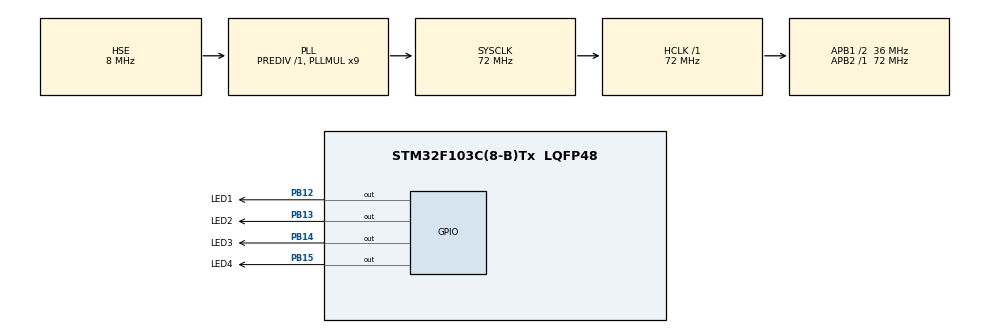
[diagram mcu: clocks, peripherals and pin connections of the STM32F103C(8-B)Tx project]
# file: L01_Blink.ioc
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Mcu.Family=STM32F1
Mcu.Name=STM32F103C(8-B)Tx
Mcu.Package=LQFP48
NVIC.PriorityGroup=NVIC_PRIORITYGROUP_4
PA13.Mode=Serial_Wire
PA13.Signal=SYS_JTMS-SWDIO
PA14.Mode=Serial_Wire
PA14.Signal=SYS_JTCK-SWCLK
PB12.GPIO_Label=LED1
PB12.PinState=GPIO_PIN_SET
PB12.Signal=GPIO_Output
PB13.GPIO_Label=LED2
PB13.PinState=GPIO_PIN_SET
PB13.Signal=GPIO_Output
PB14.GPIO_Label=LED3
PB14.PinState=GPIO_PIN_SET
PB14.Signal=GPIO_Output
PB15.GPIO_Label=LED4
PB15.PinState=GPIO_PIN_SET
PB15.Signal=GPIO_Output
PD0-OSC_IN.Mode=HSE-External-Oscillator
PD0-OSC_IN.Signal=RCC_OSC_IN
PD1-OSC_OUT.Mode=HSE-External-Oscillator
PD1-OSC_OUT.Signal=RCC_OSC_OUT
ProjectManager.HeapSize=0x200
ProjectManager.StackSize=0x400
ProjectManager.TargetToolchain=CMake
RCC.AHBFreq_Value=72000000
RCC.APB1CLKDivider=RCC_HCLK_DIV2
RCC.APB1Freq_Value=36000000
RCC.APB1TimFreq_Value=72000000
RCC.APB2Freq_Value=72000000
RCC.APB2TimFreq_Value=72000000
RCC.HCLKFreq_Value=72000000
RCC.PLLMUL=RCC_PLL_MUL9
RCC.PLLSourceVirtual=RCC_PLLSOURCE_HSE
RCC.SYSCLKFreq_VALUE=72000000
RCC.SYSCLKSource=RCC_SYSCLKSOURCE_PLLCLK
RCC.USBFreq_Value=72000000
board=custom

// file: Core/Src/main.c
/* USER CODE BEGIN Header */
/**
  ******************************************************************************
  * @file           : main.c
  * @brief          : Main program body
  ******************************************************************************
  * @attention
  *
  * Copyright (c) 2026 STMicroelectronics.
  * All rights reserved.
  *
  * This software is licensed under terms that can be found in the LICENSE file
  * in the root directory of this software component.
  * If no LICENSE file comes with this software, it is provided AS-IS.
  *
  ******************************************************************************
  */
/* USER CODE END Header */
#include "main.h"
#include "gpio.h"

/* USER CODE BEGIN Includes */
/* 包含自己的库头文件。
 * 位置很重要：必须在使用 led_init() 之前，否则编译器报
 * "implicit declaration of function"（它不认识这个函数）。
 * 放在 USER CODE 区里，CubeMX 重新生成代码时不会被删掉。 */
#include "bsp_led.h"
/* USER CODE END Includes */

void SystemClock_Config(void);

int main(void)
{

  /* MCU Configuration--------------------------------------------------------*/

  /* Reset of all peripherals, Initializes the Flash interface and the Systick. */
  HAL_Init();

  /* Configure the system clock */
  SystemClock_Config();

  /* Initialize all configured peripherals */
  MX_GPIO_Init();
  /* USER CODE BEGIN 2 */

  /* 初始化 LED 库：四颗灯全灭、退出闪烁模式。
   * 注意：GPIO 的时钟和模式已由上面的 MX_GPIO_Init() 配好，
   *      led_init() 只负责把逻辑状态设为"全灭"。 */
  led_init();

  /* 让四颗灯每 500ms 翻转一次 = 亮 500ms + 灭 500ms = 1Hz 闪烁。
   * 这个函数只记录参数就返回，不会阻塞。 */
  led_blink(LED_1, 500);
  led_blink(LED_2, 500);
  led_blink(LED_3, 500);
  led_blink(LED_4, 500);

  /* USER CODE END 2 */

  /* Infinite loop */
  while (1)
  {

    /* USER CODE BEGIN 3 */

    /* 每轮循环调用一次，由内部比较时间来决定要不要翻转。
     * 这里没有 HAL_Delay —— 主循环转得飞快（每秒几十万次），
     * 但 led_poll() 只在到达 period_ms 时才真正动一次引脚。 */
    led_poll();

  }
  /* USER CODE END 3 */
}

void SystemClock_Config(void)
{
  RCC_OscInitTypeDef RCC_OscInitStruct = {0};
  RCC_ClkInitTypeDef RCC_ClkInitStruct = {0};

  /** Initializes the RCC Oscillators according to the specified parameters
  * in the RCC_OscInitTypeDef structure.
  */
  RCC_OscInitStruct.OscillatorType = RCC_OSCILLATORTYPE_HSE;
  RCC_OscInitStruct.HSEState = RCC_HSE_ON;
  RCC_OscInitStruct.HSEPredivValue = RCC_HSE_PREDIV_DIV1;
  RCC_OscInitStruct.HSIState = RCC_HSI_ON;
  RCC_OscInitStruct.PLL.PLLState = RCC_PLL_ON;
  RCC_OscInitStruct.PLL.PLLSource = RCC_PLLSOURCE_HSE;
  RCC_OscInitStruct.PLL.PLLMUL = RCC_PLL_MUL9;
  if (HAL_RCC_OscConfig(&RCC_OscInitStruct) != HAL_OK)
  {
    Error_Handler();
  }

  /** Initializes the CPU, AHB and APB buses clocks
  */
  RCC_ClkInitStruct.ClockType = RCC_CLOCKTYPE_HCLK|RCC_CLOCKTYPE_SYSCLK
                              |RCC_CLOCKTYPE_PCLK1|RCC_CLOCKTYPE_PCLK2;
  RCC_ClkInitStruct.SYSCLKSource = RCC_SYSCLKSOURCE_PLLCLK;
  RCC_ClkInitStruct.AHBCLKDivider = RCC_SYSCLK_DIV1;
  RCC_ClkInitStruct.APB1CLKDivider = RCC_HCLK_DIV2;
  RCC_ClkInitStruct.APB2CLKDivider = RCC_HCLK_DIV1;

  if (HAL_RCC_ClockConfig(&RCC_ClkInitStruct, FLASH_LATENCY_2) != HAL_OK)
  {
    Error_Handler();
  }
}

void Error_Handler(void)
{
  __disable_irq();
  while (1)
  {
  }
}
